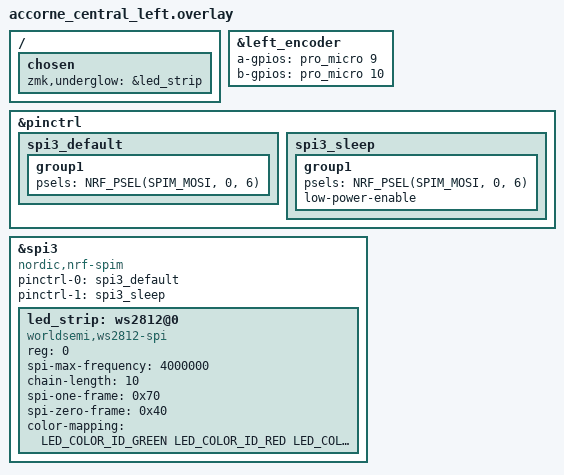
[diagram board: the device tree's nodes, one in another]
#include "accorne.dtsi"
#include <dt-bindings/led/led.h>

&left_encoder {
    status = "okay";
    a-gpios = <&pro_micro 9 (GPIO_ACTIVE_HIGH | GPIO_PULL_UP)>;
    b-gpios = <&pro_micro 10 (GPIO_ACTIVE_HIGH | GPIO_PULL_UP)>;
};

// &pro_micro_i2c {
//     oled: ssd1306@3c {
//         compatible = "solomon,ssd1306fb";
//         reg = <0x3c>;
//         width = <128>;
//         height = <32>;
//         segment-offset = <0>;
//         page-offset = <0>;
//         display-offset = <0>;
//         multiplex-ratio = <31>;
//         segment-remap;
//         com-invdir;
//         com-sequential;
//         inversion-on;
//         prechargep = <0x22>;
//     };
// };
// 
// / {
//     chosen {
//         zephyr,display = &oled;
//     };
// };



&pinctrl {
    spi3_default: spi3_default {
        group1 {
            psels = <NRF_PSEL(SPIM_MOSI, 0, 6)>;
        };
    };

    spi3_sleep: spi3_sleep {
        group1 {
            psels = <NRF_PSEL(SPIM_MOSI, 0, 6)>;
            low-power-enable;
        };
    };
};

&spi3 {
    compatible = "nordic,nrf-spim";
    status = "okay";

    pinctrl-0 = <&spi3_default>;
    pinctrl-1 = <&spi3_sleep>;
    pinctrl-names = "default", "sleep";

    led_strip: ws2812@0 {
        compatible = "worldsemi,ws2812-spi";

        /* SPI */
        reg = <0>; /* ignored, but necessary for SPI bindings */
        spi-max-frequency = <4000000>;

        /* WS2812 */
        chain-length = <10>; /* arbitrary; change at will */
        spi-one-frame = <0x70>;
        spi-zero-frame = <0x40>;

        color-mapping = <LED_COLOR_ID_GREEN LED_COLOR_ID_RED LED_COLOR_ID_BLUE>;
    };
};

/ {
    chosen {
        zmk,underglow = &led_strip;
    };
};
